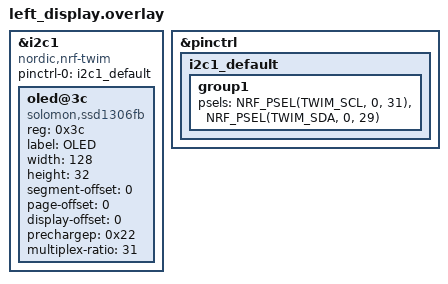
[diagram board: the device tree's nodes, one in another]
&i2c1 {
    compatible = "nordic,nrf-twim";
    status = "okay";

    pinctrl-0 = <&i2c1_default>;
    pinctrl-names = "default";

    oled@3c {
        compatible = "solomon,ssd1306fb";
        reg = <0x3c>;
        label = "OLED";
        width = <128>;
        height = <32>;
        segment-offset = <0>;
        page-offset = <0>;
        display-offset = <0>;
        prechargep = <0x22>;
        multiplex-ratio = <31>;
        // reset-gpios = <&gpio0 10 GPIO_ACTIVE_LOW>; // Only if you wired it
    };
};

&pinctrl {
    i2c1_default: i2c1_default {
        group1 {
            psels = <NRF_PSEL(TWIM_SCL, 0, 31)>,
                    <NRF_PSEL(TWIM_SDA, 0, 29)>;
        };
    };
};
